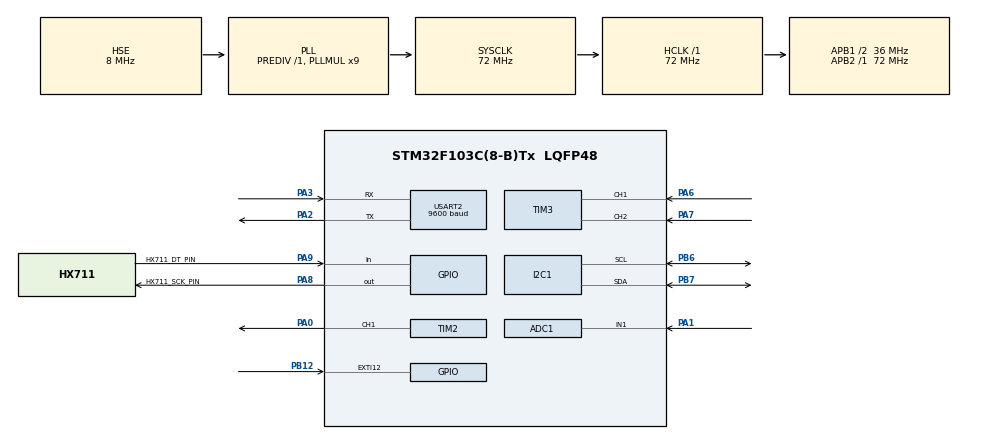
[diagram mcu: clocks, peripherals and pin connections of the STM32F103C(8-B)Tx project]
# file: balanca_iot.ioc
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ADC1.Channel-0\#ChannelRegularConversion=ADC_CHANNEL_1
ADC1.NbrOfConversionFlag=1
ADC1.Rank-0\#ChannelRegularConversion=1
ADC1.SamplingTime-0\#ChannelRegularConversion=ADC_SAMPLETIME_1CYCLE_5
ADC1.master=1
Mcu.Family=STM32F1
Mcu.Name=STM32F103C(8-B)Tx
Mcu.Package=LQFP48
NVIC.EXTI15_10_IRQn=true\:0\:0\:false\:false\:true\:true\:true\:true
NVIC.PriorityGroup=NVIC_PRIORITYGROUP_4
PA0-WKUP.Signal=S_TIM2_CH1_ETR
PA1.Signal=ADCx_IN1
PA13.Mode=Serial_Wire
PA13.Signal=SYS_JTMS-SWDIO
PA14.Mode=Serial_Wire
PA14.Signal=SYS_JTCK-SWCLK
PA2.Mode=Asynchronous
PA2.Signal=USART2_TX
PA3.Mode=Asynchronous
PA3.Signal=USART2_RX
PA6.Signal=S_TIM3_CH1
PA7.Signal=S_TIM3_CH2
PA8.GPIO_Label=HX711_SCK_PIN
PA8.Signal=GPIO_Output
PA9.GPIO_Label=HX711_DT_PIN
PA9.Signal=GPIO_Input
PB12.GPIO_ModeDefaultEXTI=GPIO_MODE_IT_FALLING
PB12.GPIO_PuPd=GPIO_PULLUP
PB12.Signal=GPXTI12
PB6.Mode=I2C
PB6.Signal=I2C1_SCL
PB7.Mode=I2C
PB7.Signal=I2C1_SDA
PD0-OSC_IN.Mode=HSE-External-Oscillator
PD0-OSC_IN.Signal=RCC_OSC_IN
PD1-OSC_OUT.Mode=HSE-External-Oscillator
PD1-OSC_OUT.Signal=RCC_OSC_OUT
ProjectManager.HeapSize=0x200
ProjectManager.StackSize=0x400
ProjectManager.TargetToolchain=STM32CubeIDE
RCC.ADCPresc=RCC_ADCPCLK2_DIV6
RCC.AHBFreq_Value=72000000
RCC.APB1CLKDivider=RCC_HCLK_DIV2
RCC.APB1Freq_Value=36000000
RCC.APB1TimFreq_Value=72000000
RCC.APB2Freq_Value=72000000
RCC.APB2TimFreq_Value=72000000
RCC.HCLKFreq_Value=72000000
RCC.PLLMUL=RCC_PLL_MUL9
RCC.PLLSourceVirtual=RCC_PLLSOURCE_HSE
RCC.SYSCLKFreq_VALUE=72000000
RCC.SYSCLKSource=RCC_SYSCLKSOURCE_PLLCLK
RCC.USBFreq_Value=72000000
SH.ADCx_IN1.0=ADC1_IN1,IN1
SH.S_TIM2_CH1_ETR.0=TIM2_CH1,PWM Generation1 CH1
SH.S_TIM3_CH1.0=TIM3_CH1,Encoder_Interface
SH.S_TIM3_CH2.0=TIM3_CH2,Encoder_Interface
TIM1.Prescaler=71
TIM2.AutoReloadPreload=TIM_AUTORELOAD_PRELOAD_ENABLE
TIM2.Channel-PWM\ Generation1\ CH1=TIM_CHANNEL_1
TIM2.Period=999
TIM2.Prescaler=71
TIM3.EncoderMode=TIM_ENCODERMODE_TI12
TIM3.IC1Filter=10
USART2.BaudRate=9600
USART2.VirtualMode=VM_ASYNC
VP_TIM1_VS_ClockSourceINT.Mode=Internal
VP_TIM2_VS_ClockSourceINT.Mode=Internal
board=custom

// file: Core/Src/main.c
/* USER CODE BEGIN Header */
/**
  ******************************************************************************
  * @file           : main.c
  * @brief          : Main program body
  ******************************************************************************
  * @attention
  *
  * Copyright (c) 2026 STMicroelectronics.
  * All rights reserved.
  *
  * This software is licensed under terms that can be found in the LICENSE file
  * in the root directory of this software component.
  * If no LICENSE file comes with this software, it is provided AS-IS.
  *
  ******************************************************************************
  */
/* USER CODE END Header */
#include "main.h"

/* USER CODE BEGIN Includes */
#include "menu.h"
#include <stdio.h>
#include "hx711.h"
#include "weight_module.h"
#include "ssd1306.h"
#include "ssd1306_fonts.h"
#include <string.h>
/* USER CODE END Includes */

/* USER CODE BEGIN PD */

// Endereço I2C do ESP32 configurado como escravo
#define ESP32_SLAVE_ADDR   (0x08 << 1)

// Pino de dados do HX711
#define DT_PIN HX711_DT_PIN_Pin

// Porta correspondente ao pino DT
#define DT_PORT HX711_DT_PIN_GPIO_Port

// Pino de clock do HX711
#define SCK_PIN HX711_SCK_PIN_Pin

// Porta correspondente ao pino SCK
#define SCK_PORT HX711_SCK_PIN_GPIO_Port
/* USER CODE END PD */

ADC_HandleTypeDef hadc1;

I2C_HandleTypeDef hi2c1;
I2C_HandleTypeDef hi2c2;

TIM_HandleTypeDef htim1;
TIM_HandleTypeDef htim2;
TIM_HandleTypeDef htim3;

UART_HandleTypeDef huart2;

/* USER CODE BEGIN PV */
// Estrutura responsável pela comunicação com o módulo HX711
hx711_t balanca;

// Flag utilizada para solicitar a operação de tara
volatile uint8_t flag_solicita_tara = 0;

// Peso limite configurado pelo usuário
extern float limit_weight;

// Estado atual da máquina de estados da interface
extern volatile BalancaState current_state;

// Armazena o último estado enviado ao ESP32, evitando envio repetitivo
static BalancaState last_state_sent = TELA_PRINCIPAL;
static uint32_t last_report_tick = 0;

// Intervalo entre atualizações enviadas ao ESP32
#define ANDAMENTO_INTERVAL_MS 300
/* USER CODE END PV */

void SystemClock_Config(void);
static void MX_GPIO_Init(void);
static void MX_ADC1_Init(void);
static void MX_TIM2_Init(void);
static void MX_I2C1_Init(void);
static void MX_TIM3_Init(void);
static void MX_TIM1_Init(void);
static void MX_USART2_UART_Init(void);

int main(void)
{

  /* MCU Configuration--------------------------------------------------------*/

  /* Reset of all peripherals, Initializes the Flash interface and the Systick. */
  HAL_Init();

  /* Configure the system clock */
  SystemClock_Config();

  /* Initialize all configured peripherals */
  MX_GPIO_Init();
  MX_ADC1_Init();
  MX_TIM2_Init();
  MX_I2C1_Init();
  MX_TIM3_Init();
  MX_TIM1_Init();
  MX_USART2_UART_Init();
  /* USER CODE BEGIN 2 */

 /* INICIALIZACAO DA INTERFACE DO USUARIO */
  HAL_Delay(100);
  menu_init(&htim3);
  ssd1306_Init();

  /* INICIALIZACAO DOS PERIFERICOS DE TEMPO */
  HAL_TIM_Encoder_Start(&htim3, TIM_CHANNEL_ALL);
  HAL_TIM_Base_Start(&htim1);
  HAL_TIM_PWM_Start(&htim2, TIM_CHANNEL_1);

  /* INICIALIZACAO DO MODULO HX711 */
  hx711_init(&balanca, SCK_PORT, SCK_PIN, DT_PORT, DT_PIN);
  hx711_coef_set(&balanca, 80.0);
  hx711_tare(&balanca, 10);

  float peso_atual;
  /* USER CODE END 2 */

  /* Infinite loop */
  /* USER CODE END 2 */

  /* Infinite loop */
  /* USER CODE BEGIN WHILE */
  while (1)
  {
	  // Atualizando o brilho do display de forma automatica via ADC
	  update_bright_display_oled();

    // Processamento da operação de tara
	  if (flag_solicita_tara == 1){

        ssd1306_Fill(Black);
        ssd1306_SetCursor(20, 25);
        ssd1306_WriteString("Zerando...", Font_11x18, White);
        ssd1306_UpdateScreen();
        hx711_tare(&balanca, 10);
        flag_solicita_tara = 0;
    }

    // Leitura do peso atual
	  peso_atual = measure_weight(&balanca);

    // Verifica se o booleano da mensagem está ativo
    if (msg_ready){
          // Buffer retornando on, ativa o pino 13
	  	    if (strcmp(rx_buffer, "on") == 0)
	  	    {
	  	        HAL_GPIO_WritePin(GPIOB, GPIO_PIN_13, GPIO_PIN_SET);
	  	    }
          // Buffer retornando off, desativa o pino 13
	  	    else if (strcmp(rx_buffer, "off") == 0)
	  	    {
	  	        HAL_GPIO_WritePin(GPIOB, GPIO_PIN_13, GPIO_PIN_RESET);
	  	    }

          //Redefine o boolean para zero, pensando na proxima recepção
	  	    msg_ready = 0;
	  }

    // Atualiza a intensidade do LED conforme o peso medido
    update_led_pwm(peso_atual, limit_weight, current_state);

    // Comunicação com o ESP32
		if (current_state == TELA_PESAGEM && last_state_sent != TELA_PESAGEM)
    {
        // Acabou de entrar na tela de pesagem
        send_json_to_esp32(limit_weight, peso_atual, "iniciado");
        last_state_sent = TELA_PESAGEM;
        last_report_tick = HAL_GetTick();
    }
    else if (current_state == TELA_PESAGEM && last_state_sent == TELA_PESAGEM)
    {
        // Continua pesando: envia "andamento" no máximo a cada ANDAMENTO_INTERVAL_MS
        if (HAL_GetTick() - last_report_tick >= ANDAMENTO_INTERVAL_MS)
        {
            send_json_to_esp32(limit_weight, peso_atual, "andamento");
            last_report_tick = HAL_GetTick();
        }
    }
    else if (current_state != TELA_PESAGEM && last_state_sent == TELA_PESAGEM)
    {
        // Acabou de sair da tela de pesagem
        send_json_to_esp32(limit_weight, peso_atual, "finalizado");
        last_state_sent = current_state;
    }
    else
    {
        last_state_sent = current_state;
    }

    // Atualização da interface gráfica

		uint32_t valor_encoder = __HAL_TIM_GET_COUNTER(&htim3);

		menu_update(peso_atual,valor_encoder);

    /* USER CODE END WHILE */

  }

  /* USER CODE END 3 */
}

void SystemClock_Config(void)
{
  RCC_OscInitTypeDef RCC_OscInitStruct = {0};
  RCC_ClkInitTypeDef RCC_ClkInitStruct = {0};
  RCC_PeriphCLKInitTypeDef PeriphClkInit = {0};

  /** Initializes the RCC Oscillators according to the specified parameters
  * in the RCC_OscInitTypeDef structure.
  */
  RCC_OscInitStruct.OscillatorType = RCC_OSCILLATORTYPE_HSE;
  RCC_OscInitStruct.HSEState = RCC_HSE_ON;
  RCC_OscInitStruct.HSEPredivValue = RCC_HSE_PREDIV_DIV1;
  RCC_OscInitStruct.HSIState = RCC_HSI_ON;
  RCC_OscInitStruct.PLL.PLLState = RCC_PLL_ON;
  RCC_OscInitStruct.PLL.PLLSource = RCC_PLLSOURCE_HSE;
  RCC_OscInitStruct.PLL.PLLMUL = RCC_PLL_MUL9;
  if (HAL_RCC_OscConfig(&RCC_OscInitStruct) != HAL_OK)
  {
    Error_Handler();
  }

  /** Initializes the CPU, AHB and APB buses clocks
  */
  RCC_ClkInitStruct.ClockType = RCC_CLOCKTYPE_HCLK|RCC_CLOCKTYPE_SYSCLK
                              |RCC_CLOCKTYPE_PCLK1|RCC_CLOCKTYPE_PCLK2;
  RCC_ClkInitStruct.SYSCLKSource = RCC_SYSCLKSOURCE_PLLCLK;
  RCC_ClkInitStruct.AHBCLKDivider = RCC_SYSCLK_DIV1;
  RCC_ClkInitStruct.APB1CLKDivider = RCC_HCLK_DIV2;
  RCC_ClkInitStruct.APB2CLKDivider = RCC_HCLK_DIV1;

  if (HAL_RCC_ClockConfig(&RCC_ClkInitStruct, FLASH_LATENCY_2) != HAL_OK)
  {
    Error_Handler();
  }
  PeriphClkInit.PeriphClockSelection = RCC_PERIPHCLK_ADC;
  PeriphClkInit.AdcClockSelection = RCC_ADCPCLK2_DIV6;
  if (HAL_RCCEx_PeriphCLKConfig(&PeriphClkInit) != HAL_OK)
  {
    Error_Handler();
  }
}

static void MX_ADC1_Init(void)
{

  ADC_ChannelConfTypeDef sConfig = {0};

  /** Common config
  */
  hadc1.Instance = ADC1;
  hadc1.Init.ScanConvMode = ADC_SCAN_DISABLE;
  hadc1.Init.ContinuousConvMode = DISABLE;
  hadc1.Init.DiscontinuousConvMode = DISABLE;
  hadc1.Init.ExternalTrigConv = ADC_SOFTWARE_START;
  hadc1.Init.DataAlign = ADC_DATAALIGN_RIGHT;
  hadc1.Init.NbrOfConversion = 1;
  if (HAL_ADC_Init(&hadc1) != HAL_OK)
  {
    Error_Handler();
  }

  /** Configure Regular Channel
  */
  sConfig.Channel = ADC_CHANNEL_1;
  sConfig.Rank = ADC_REGULAR_RANK_1;
  sConfig.SamplingTime = ADC_SAMPLETIME_1CYCLE_5;
  if (HAL_ADC_ConfigChannel(&hadc1, &sConfig) != HAL_OK)
  {
    Error_Handler();
  }

}

static void MX_I2C1_Init(void)
{

  hi2c1.Instance = I2C1;
  hi2c1.Init.ClockSpeed = 100000;
  hi2c1.Init.DutyCycle = I2C_DUTYCYCLE_2;
  hi2c1.Init.OwnAddress1 = 0;
  hi2c1.Init.AddressingMode = I2C_ADDRESSINGMODE_7BIT;
  hi2c1.Init.DualAddressMode = I2C_DUALADDRESS_DISABLE;
  hi2c1.Init.OwnAddress2 = 0;
  hi2c1.Init.GeneralCallMode = I2C_GENERALCALL_DISABLE;
  hi2c1.Init.NoStretchMode = I2C_NOSTRETCH_DISABLE;
  if (HAL_I2C_Init(&hi2c1) != HAL_OK)
  {
    Error_Handler();
  }

}

static void MX_TIM1_Init(void)
{

  TIM_ClockConfigTypeDef sClockSourceConfig = {0};
  TIM_MasterConfigTypeDef sMasterConfig = {0};

  htim1.Instance = TIM1;
  htim1.Init.Prescaler = 71;
  htim1.Init.CounterMode = TIM_COUNTERMODE_UP;
  htim1.Init.Period = 65535;
  htim1.Init.ClockDivision = TIM_CLOCKDIVISION_DIV1;
  htim1.Init.RepetitionCounter = 0;
  htim1.Init.AutoReloadPreload = TIM_AUTORELOAD_PRELOAD_DISABLE;
  if (HAL_TIM_Base_Init(&htim1) != HAL_OK)
  {
    Error_Handler();
  }
  sClockSourceConfig.ClockSource = TIM_CLOCKSOURCE_INTERNAL;
  if (HAL_TIM_ConfigClockSource(&htim1, &sClockSourceConfig) != HAL_OK)
  {
    Error_Handler();
  }
  sMasterConfig.MasterOutputTrigger = TIM_TRGO_RESET;
  sMasterConfig.MasterSlaveMode = TIM_MASTERSLAVEMODE_DISABLE;
  if (HAL_TIMEx_MasterConfigSynchronization(&htim1, &sMasterConfig) != HAL_OK)
  {
    Error_Handler();
  }

}

static void MX_TIM2_Init(void)
{

  TIM_ClockConfigTypeDef sClockSourceConfig = {0};
  TIM_MasterConfigTypeDef sMasterConfig = {0};
  TIM_OC_InitTypeDef sConfigOC = {0};

  htim2.Instance = TIM2;
  htim2.Init.Prescaler = 71;
  htim2.Init.CounterMode = TIM_COUNTERMODE_UP;
  htim2.Init.Period = 999;
  htim2.Init.ClockDivision = TIM_CLOCKDIVISION_DIV1;
  htim2.Init.AutoReloadPreload = TIM_AUTORELOAD_PRELOAD_ENABLE;
  if (HAL_TIM_Base_Init(&htim2) != HAL_OK)
  {
    Error_Handler();
  }
  sClockSourceConfig.ClockSource = TIM_CLOCKSOURCE_INTERNAL;
  if (HAL_TIM_ConfigClockSource(&htim2, &sClockSourceConfig) != HAL_OK)
  {
    Error_Handler();
  }
  if (HAL_TIM_PWM_Init(&htim2) != HAL_OK)
  {
    Error_Handler();
  }
  sMasterConfig.MasterOutputTrigger = TIM_TRGO_RESET;
  sMasterConfig.MasterSlaveMode = TIM_MASTERSLAVEMODE_DISABLE;
  if (HAL_TIMEx_MasterConfigSynchronization(&htim2, &sMasterConfig) != HAL_OK)
  {
    Error_Handler();
  }
  sConfigOC.OCMode = TIM_OCMODE_PWM1;
  sConfigOC.Pulse = 0;
  sConfigOC.OCPolarity = TIM_OCPOLARITY_HIGH;
  sConfigOC.OCFastMode = TIM_OCFAST_DISABLE;
  if (HAL_TIM_PWM_ConfigChannel(&htim2, &sConfigOC, TIM_CHANNEL_1) != HAL_OK)
  {
    Error_Handler();
  }
  HAL_TIM_MspPostInit(&htim2);

}

static void MX_TIM3_Init(void)
{

  TIM_Encoder_InitTypeDef sConfig = {0};
  TIM_MasterConfigTypeDef sMasterConfig = {0};

  htim3.Instance = TIM3;
  htim3.Init.Prescaler = 0;
  htim3.Init.CounterMode = TIM_COUNTERMODE_UP;
  htim3.Init.Period = 65535;
  htim3.Init.ClockDivision = TIM_CLOCKDIVISION_DIV1;
  htim3.Init.AutoReloadPreload = TIM_AUTORELOAD_PRELOAD_DISABLE;
  sConfig.EncoderMode = TIM_ENCODERMODE_TI12;
  sConfig.IC1Polarity = TIM_ICPOLARITY_RISING;
  sConfig.IC1Selection = TIM_ICSELECTION_DIRECTTI;
  sConfig.IC1Prescaler = TIM_ICPSC_DIV1;
  sConfig.IC1Filter = 10;
  sConfig.IC2Polarity = TIM_ICPOLARITY_RISING;
  sConfig.IC2Selection = TIM_ICSELECTION_DIRECTTI;
  sConfig.IC2Prescaler = TIM_ICPSC_DIV1;
  sConfig.IC2Filter = 0;
  if (HAL_TIM_Encoder_Init(&htim3, &sConfig) != HAL_OK)
  {
    Error_Handler();
  }
  sMasterConfig.MasterOutputTrigger = TIM_TRGO_RESET;
  sMasterConfig.MasterSlaveMode = TIM_MASTERSLAVEMODE_DISABLE;
  if (HAL_TIMEx_MasterConfigSynchronization(&htim3, &sMasterConfig) != HAL_OK)
  {
    Error_Handler();
  }

}

static void MX_USART2_UART_Init(void)
{

  huart2.Instance = USART2;
  huart2.Init.BaudRate = 9600;
  huart2.Init.WordLength = UART_WORDLENGTH_8B;
  huart2.Init.StopBits = UART_STOPBITS_1;
  huart2.Init.Parity = UART_PARITY_NONE;
  huart2.Init.Mode = UART_MODE_TX_RX;
  huart2.Init.HwFlowCtl = UART_HWCONTROL_NONE;
  huart2.Init.OverSampling = UART_OVERSAMPLING_16;
  if (HAL_UART_Init(&huart2) != HAL_OK)
  {
    Error_Handler();
  }

}

static void MX_GPIO_Init(void)
{
  GPIO_InitTypeDef GPIO_InitStruct = {0};

  /* GPIO Ports Clock Enable */
  __HAL_RCC_GPIOD_CLK_ENABLE();
  __HAL_RCC_GPIOA_CLK_ENABLE();
  __HAL_RCC_GPIOB_CLK_ENABLE();

  /*Configure GPIO pin Output Level */
  HAL_GPIO_WritePin(GPIOB, GPIO_PIN_13, GPIO_PIN_RESET);

  /*Configure GPIO pin Output Level */
  HAL_GPIO_WritePin(HX711_SCK_PIN_GPIO_Port, HX711_SCK_PIN_Pin, GPIO_PIN_RESET);

  /*Configure GPIO pin : PB12 */
  GPIO_InitStruct.Pin = GPIO_PIN_12;
  GPIO_InitStruct.Mode = GPIO_MODE_IT_FALLING;
  GPIO_InitStruct.Pull = GPIO_PULLUP;
  HAL_GPIO_Init(GPIOB, &GPIO_InitStruct);

  /*Configure GPIO pin : PB13 */
  GPIO_InitStruct.Pin = GPIO_PIN_13;
  GPIO_InitStruct.Mode = GPIO_MODE_OUTPUT_PP;
  GPIO_InitStruct.Pull = GPIO_NOPULL;
  GPIO_InitStruct.Speed = GPIO_SPEED_FREQ_LOW;
  HAL_GPIO_Init(GPIOB, &GPIO_InitStruct);

  /*Configure GPIO pin : HX711_SCK_PIN_Pin */
  GPIO_InitStruct.Pin = HX711_SCK_PIN_Pin;
  GPIO_InitStruct.Mode = GPIO_MODE_OUTPUT_PP;
  GPIO_InitStruct.Pull = GPIO_NOPULL;
  GPIO_InitStruct.Speed = GPIO_SPEED_FREQ_LOW;
  HAL_GPIO_Init(HX711_SCK_PIN_GPIO_Port, &GPIO_InitStruct);

  /*Configure GPIO pin : HX711_DT_PIN_Pin */
  GPIO_InitStruct.Pin = HX711_DT_PIN_Pin;
  GPIO_InitStruct.Mode = GPIO_MODE_INPUT;
  GPIO_InitStruct.Pull = GPIO_NOPULL;
  HAL_GPIO_Init(HX711_DT_PIN_GPIO_Port, &GPIO_InitStruct);

  /* EXTI interrupt init*/
  HAL_NVIC_SetPriority(EXTI15_10_IRQn, 0, 0);
  HAL_NVIC_EnableIRQ(EXTI15_10_IRQn);

}

/* USER CODE BEGIN 4 */

/**
 * @brief Callback da interrupção do botão do encoder.
 *
 * Implementa um debounce simples por software antes
 * de encaminhar o evento para a máquina de estados.
 */

void HAL_GPIO_EXTI_Callback(uint16_t GPIO_Pin){
	if(GPIO_Pin == GPIO_PIN_12){
    // Último instante em que o botão foi pressionado
		static uint32_t last_click = 0;
    // Debounce de 200 ms
		if(HAL_GetTick() - last_click > 200){
			menu_action_btn();

			last_click = HAL_GetTick();
		}
	}
}

void HAL_UART_RxCpltCallback(UART_HandleTypeDef *huart)
{

    if (rx_byte == '\n'){
        rx_buffer[rx_index] = '\0';
        msg_ready = 1;
        rx_index = 0;
    }
    else if (rx_index < sizeof(rx_buffer) - 1){
        rx_buffer[rx_index++] = rx_byte;
    }

    HAL_UART_Receive_IT(&huart2, &rx_byte, 1);

}

/* USER CODE END 4 */

void Error_Handler(void)
{
  __disable_irq();
  while (1)
  {
  }
}
